# MSP430F249 register map
Vendor: msp430gen; File version: v0.4.0
Registers are 8-bit, read-write, reset 0x0 unless marked. A register's access mark holds for its fields unless they carry their own. Offsets are from the block's base; lines under a group give offsets from that group; [hi:lo] are bit positions; {n}, {i} and the like mark numbered series; 'fields as' and 'values as' point back to an identical list; <NAME> marks a mode.

## Memory map
0x00000000 SPECIAL_FUNCTION
0x00000010 PORT_3_4
0x00000012 PORT_5_6
0x00000020 PORT_1_2
0x00000052 SYSTEM_CLOCK
0x00000054 SUPPLY_VOLTAGE_SUPERVISOR
0x00000058 COMPARATOR_A
0x0000005C USCI_A0_UART_MODE
0x00000060 USCI_A0_SPI_MODE
0x00000068 USCI_B0_I2C_MODE
0x00000068 USCI_B0_SPI_MODE
0x00000080 ADC12
0x000000CC USCI_A1_UART_MODE
0x000000D0 USCI_A1_SPI_MODE
0x000000D8 USCI_B1_I2C_MODE
0x000000D8 USCI_B1_SPI_MODE
0x0000011E TIMER_B7
0x00000120 WATCHDOG_TIMER
0x00000128 FLASH
0x0000012E TIMER_A3
0x00000130 MULTIPLIER
0x000010C0 TLV_CALIBRATION_DATA
0x000010F8 CALIBRATION_DATA
0x0000FFC0 _INTERRUPTS

## Interrupts
{n} RESERVED{n} (_INTERRUPTS) (n=0..15) — {0xFFC0+2n} Reserved Int. Vector {n}
16 USCIAB1TX (_INTERRUPTS) — 0xFFE0 USCI A1/B1 Transmit
17 USCIAB1RX (_INTERRUPTS) — 0xFFE2 USCI A1/B1 Receive
18 PORT1 (_INTERRUPTS) — 0xFFE4 Port 1
19 PORT2 (_INTERRUPTS) — 0xFFE6 Port 2
20 RESERVED20 (_INTERRUPTS) — 0xFFE8 Reserved Int. Vector 20
21 ADC12 (_INTERRUPTS) — 0xFFEA ADC
22 USCIAB0TX (_INTERRUPTS) — 0xFFEC USCI A0/B0 Transmit
23 USCIAB0RX (_INTERRUPTS) — 0xFFEE USCI A0/B0 Receive
24 TIMERA1 (_INTERRUPTS) — 0xFFF0 Timer A CC1-2, TA
25 TIMERA0 (_INTERRUPTS) — 0xFFF2 Timer A CC0
26 WDT (_INTERRUPTS) — 0xFFF4 Watchdog Timer
27 COMPARATORA (_INTERRUPTS) — 0xFFF6 Comparator A
28 TIMERB1 (_INTERRUPTS) — 0xFFF8 Timer B CC1-6, TB
29 TIMERB0 (_INTERRUPTS) — 0xFFFA Timer B CC0
30 NMI (_INTERRUPTS) — 0xFFFC Non-maskable

## SPECIAL_FUNCTION
Base 0x00000000
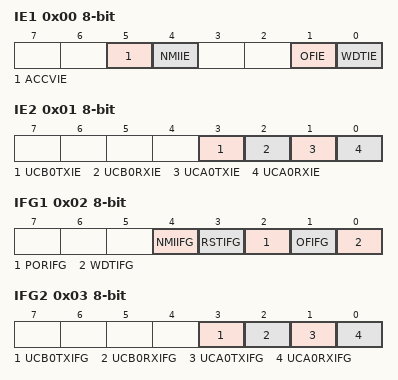
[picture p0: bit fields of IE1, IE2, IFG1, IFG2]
0x00 IE1 — Interrupt Enable 1
  [5] ACCVIE — Flash Access Violation Interrupt Enable
  [4] NMIIE — NMI Interrupt Enable
  [1] OFIE — Osc. Fault Interrupt Enable
  [0] WDTIE — Watchdog Interrupt Enable
0x01 IE2 — Interrupt Enable 2
  [3] UCB0TXIE, [2] UCB0RXIE, [1] UCA0TXIE, [0] UCA0RXIE
0x02 IFG1 — Interrupt Flag 1
  [4] NMIIFG — NMI Interrupt Flag
  [3] RSTIFG — Reset Interrupt Flag
  [2] PORIFG — Power On Interrupt Flag
  [1] OFIFG — Osc. Fault Interrupt Flag
  [0] WDTIFG — Watchdog Interrupt Flag
0x03 IFG2 — Interrupt Flag 2
  [3] UCB0TXIFG, [2] UCB0RXIFG, [1] UCA0TXIFG, [0] UCA0RXIFG
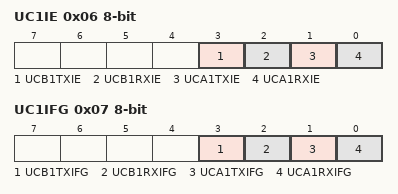
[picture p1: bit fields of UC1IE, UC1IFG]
0x06 UC1IE — USCI 1 Interrupt Enable
  [3] UCB1TXIE, [2] UCB1RXIE, [1] UCA1TXIE, [0] UCA1RXIE
0x07 UC1IFG — ISCI 1 Interrupt Flags
  [3] UCB1TXIFG, [2] UCB1RXIFG, [1] UCA1TXIFG, [0] UCA1RXIFG

## PORT_3_4
Base 0x00000010
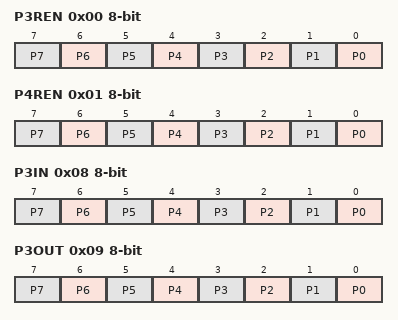
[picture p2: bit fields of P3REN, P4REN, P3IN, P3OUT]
0x00 P3REN — Port 3 Resistor Enable
  [n] P{n} (n=0..7)
0x01 P4REN — Port 4 Resistor Enable
  [n] P{n} (n=0..7)
0x08 P3IN — Port 3 Input
  [n] P{n} (n=0..7)
0x09 P3OUT — Port 3 Output
  [n] P{n} (n=0..7)
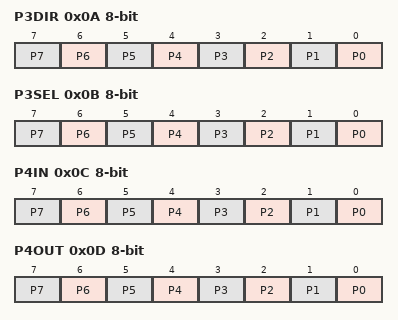
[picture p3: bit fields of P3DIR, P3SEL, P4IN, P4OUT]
0x0A P3DIR — Port 3 Direction
  [n] P{n} (n=0..7)
0x0B P3SEL — Port 3 Selection
  [n] P{n} (n=0..7)
0x0C P4IN — Port 4 Input
  [n] P{n} (n=0..7)
0x0D P4OUT — Port 4 Output
  [n] P{n} (n=0..7)
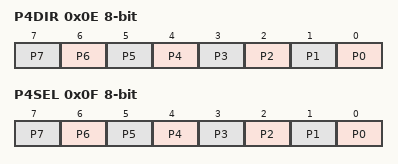
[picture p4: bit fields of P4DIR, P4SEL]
0x0E P4DIR — Port 4 Direction
  [n] P{n} (n=0..7)
0x0F P4SEL — Port 4 Selection
  [n] P{n} (n=0..7)

## PORT_5_6
Base 0x00000012
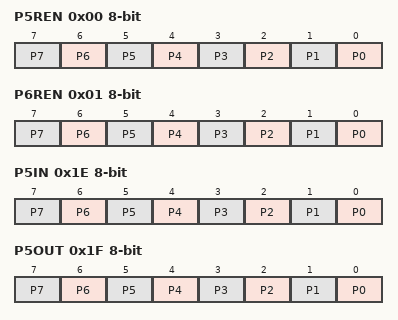
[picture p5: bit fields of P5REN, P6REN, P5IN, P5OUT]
0x00 P5REN — Port 5 Resistor Enable
  [n] P{n} (n=0..7)
0x01 P6REN — Port 6 Resistor Enable
  [n] P{n} (n=0..7)
0x1E P5IN — Port 5 Input
  [n] P{n} (n=0..7)
0x1F P5OUT — Port 5 Output
  [n] P{n} (n=0..7)
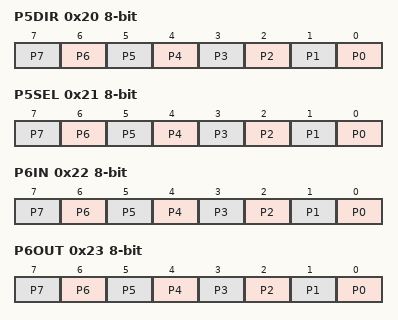
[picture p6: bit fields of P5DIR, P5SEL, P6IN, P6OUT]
0x20 P5DIR — Port 5 Direction
  [n] P{n} (n=0..7)
0x21 P5SEL — Port 5 Selection
  [n] P{n} (n=0..7)
0x22 P6IN — Port 6 Input
  [n] P{n} (n=0..7)
0x23 P6OUT — Port 6 Output
  [n] P{n} (n=0..7)
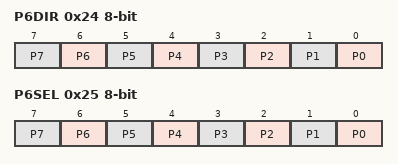
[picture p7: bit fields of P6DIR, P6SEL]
0x24 P6DIR — Port 6 Direction
  [n] P{n} (n=0..7)
0x25 P6SEL — Port 6 Selection
  [n] P{n} (n=0..7)

## PORT_1_2
Base 0x00000020
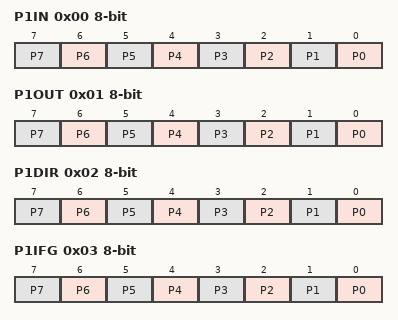
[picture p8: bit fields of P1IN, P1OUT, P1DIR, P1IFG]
0x00 P1IN — Port 1 Input
  [n] P{n} (n=0..7)
0x01 P1OUT — Port 1 Output
  [n] P{n} (n=0..7)
0x02 P1DIR — Port 1 Direction
  [n] P{n} (n=0..7)
0x03 P1IFG — Port 1 Interrupt Flag
  [n] P{n} (n=0..7)
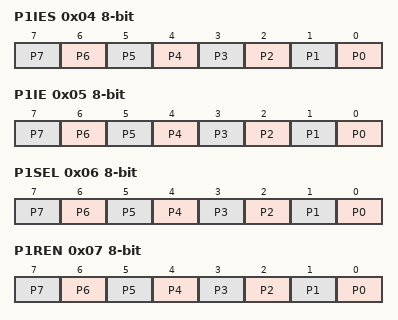
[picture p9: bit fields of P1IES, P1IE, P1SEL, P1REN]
0x04 P1IES — Port 1 Interrupt Edge Select
  [n] P{n} (n=0..7)
0x05 P1IE — Port 1 Interrupt Enable
  [n] P{n} (n=0..7)
0x06 P1SEL — Port 1 Selection
  [n] P{n} (n=0..7)
0x07 P1REN — Port 1 Resistor Enable
  [n] P{n} (n=0..7)
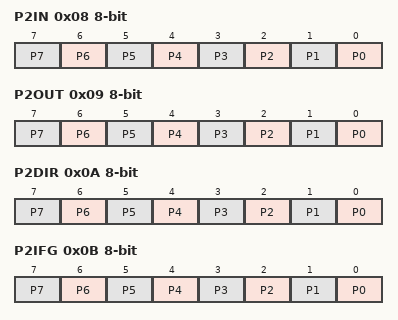
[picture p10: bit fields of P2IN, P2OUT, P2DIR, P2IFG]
0x08 P2IN — Port 2 Input
  [n] P{n} (n=0..7)
0x09 P2OUT — Port 2 Output
  [n] P{n} (n=0..7)
0x0A P2DIR — Port 2 Direction
  [n] P{n} (n=0..7)
0x0B P2IFG — Port 2 Interrupt Flag
  [n] P{n} (n=0..7)
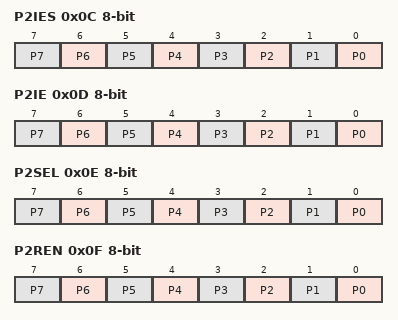
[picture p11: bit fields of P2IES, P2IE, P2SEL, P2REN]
0x0C P2IES — Port 2 Interrupt Edge Select
  [n] P{n} (n=0..7)
0x0D P2IE — Port 2 Interrupt Enable
  [n] P{n} (n=0..7)
0x0E P2SEL — Port 2 Selection
  [n] P{n} (n=0..7)
0x0F P2REN — Port 2 Resistor Enable
  [n] P{n} (n=0..7)
